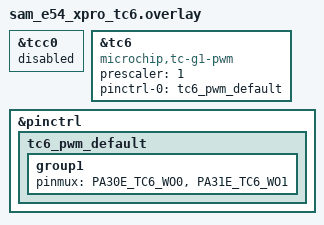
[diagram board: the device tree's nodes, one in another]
/*
 * Copyright (c) 2025 Microchip Technology Inc.
 *
 * SPDX-License-Identifier: Apache-2.0
 */

&tcc0 {
	status = "disabled";
};

&tc6 {
	status = "okay";
	compatible = "microchip,tc-g1-pwm";
	prescaler = <1>;
	#pwm-cells = <3>;
	pinctrl-0 = <&tc6_pwm_default>;
	pinctrl-names = "default";
};

&pinctrl {
	tc6_pwm_default: tc6_pwm_default {
		group1 {
			pinmux = <PA30E_TC6_WO0>,
				 <PA31E_TC6_WO1>;
		};
	};
};
